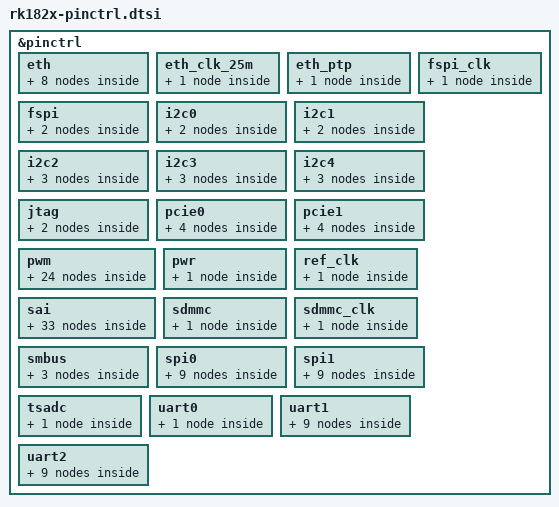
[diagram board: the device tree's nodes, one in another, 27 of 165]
// SPDX-License-Identifier: (GPL-2.0+ OR MIT)
/*
 * Copyright (c) 2026 Rockchip Electronics Co., Ltd.
 */

#include <dt-bindings/pinctrl/rockchip.h>
#include "rk182x-pinconf.dtsi"

/*
 * This file is auto generated by pin2dts tool, please keep these code
 * by adding changes at end of this file.
 */
&pinctrl {
	eth {
		/omit-if-no-ref/
		eth_miim_pins: eth-miim-pins {
			rockchip,pins =
				<1 RK_PC2 1 &pcfg_pull_none>,
				<1 RK_PC3 1 &pcfg_pull_none>;
		};

		/omit-if-no-ref/
		eth_mclk_pins: eth-mclk-pins {
			rockchip,pins =
				<1 RK_PC5 1 &pcfg_pull_none>;
		};

		/omit-if-no-ref/
		eth_rx_bus2_pins: eth-rx-bus2-pins {
			rockchip,pins =
				<1 RK_PC0 1 &pcfg_pull_none>,
				<1 RK_PB4 1 &pcfg_pull_none>,
				<1 RK_PB5 1 &pcfg_pull_none>;
		};

		/omit-if-no-ref/
		eth_tx_bus2_pins: eth-tx-bus2-pins {
			rockchip,pins =
				<1 RK_PB2 1 &pcfg_pull_none>,
				<1 RK_PA6 1 &pcfg_pull_none>,
				<1 RK_PA7 1 &pcfg_pull_none>;
		};

		/omit-if-no-ref/
		eth_rgmii_clk_pins: eth-rgmii-clk-pins {
			rockchip,pins =
				<1 RK_PC1 1 &pcfg_pull_none>,
				<1 RK_PB3 1 &pcfg_pull_none>;
		};

		/omit-if-no-ref/
		eth_rgmii_bus_pins: eth-rgmii-bus-pins {
			rockchip,pins =
				<1 RK_PB6 1 &pcfg_pull_none>,
				<1 RK_PB7 1 &pcfg_pull_none>,
				<1 RK_PB0 1 &pcfg_pull_none>,
				<1 RK_PB1 1 &pcfg_pull_none>;
		};

		/omit-if-no-ref/
		eth_ppsclk_pins: eth-ppsclk-pins {
			rockchip,pins =
				<1 RK_PC7 1 &pcfg_pull_none>;
		};

		/omit-if-no-ref/
		eth_ppstrig_pins: eth-ppstrig-pins {
			rockchip,pins =
				<1 RK_PD0 1 &pcfg_pull_none>;
		};
	};

	eth_clk_25m {
		/omit-if-no-ref/
		eth_clk_25m_out_pins: eth-clk-25m-out-pins {
			rockchip,pins =
				<1 RK_PC4 1 &pcfg_pull_none>;
		};
	};

	eth_ptp {
		/omit-if-no-ref/
		eth_ptp_refclk_pins: eth-ptp-refclk-pins {
			rockchip,pins =
				<1 RK_PC6 1 &pcfg_pull_none>;
		};
	};

	fspi {
		/omit-if-no-ref/
		fspi_bus4_pins: fspi-bus4-pins {
			rockchip,pins =
				<0 RK_PC4 1 &pcfg_pull_none>,
				<0 RK_PC5 1 &pcfg_pull_none>,
				<0 RK_PC6 1 &pcfg_pull_none>,
				<0 RK_PC7 1 &pcfg_pull_none>;
		};

		/omit-if-no-ref/
		fspi_csn_pins: fspi-csn-pins {
			rockchip,pins =
				<0 RK_PD0 1 &pcfg_pull_none>;
		};
	};

	fspi_clk {
		/omit-if-no-ref/
		fspi_clk_out_pins: fspi-clk-out-pins {
			rockchip,pins =
				<0 RK_PD1 1 &pcfg_pull_none>;
		};
	};

	i2c0 {
		/omit-if-no-ref/
		i2c0m0_pins: i2c0m0-pins {
			rockchip,pins =
				<0 RK_PA5 1 &pcfg_pull_none_smt>,
				<0 RK_PA6 1 &pcfg_pull_none_smt>;
		};

		/omit-if-no-ref/
		i2c0m1_pins: i2c0m1-pins {
			rockchip,pins =
				<1 RK_PB0 2 &pcfg_pull_none_smt>,
				<1 RK_PB1 2 &pcfg_pull_none_smt>;
		};
	};

	i2c1 {
		/omit-if-no-ref/
		i2c1m0_pins: i2c1m0-pins {
			rockchip,pins =
				<0 RK_PA7 1 &pcfg_pull_none_smt>,
				<0 RK_PB0 1 &pcfg_pull_none_smt>;
		};

		/omit-if-no-ref/
		i2c1m1_pins: i2c1m1-pins {
			rockchip,pins =
				<1 RK_PB3 2 &pcfg_pull_none_smt>,
				<1 RK_PB6 2 &pcfg_pull_none_smt>;
		};
	};

	i2c2 {
		/omit-if-no-ref/
		i2c2m0_pins: i2c2m0-pins {
			rockchip,pins =
				<0 RK_PB5 1 &pcfg_pull_none_smt>,
				<0 RK_PB6 1 &pcfg_pull_none_smt>;
		};

		/omit-if-no-ref/
		i2c2m1_pins: i2c2m1-pins {
			rockchip,pins =
				<1 RK_PC4 2 &pcfg_pull_none_smt>,
				<1 RK_PC5 2 &pcfg_pull_none_smt>;
		};

		/omit-if-no-ref/
		i2c2m2_pins: i2c2m2-pins {
			rockchip,pins =
				<1 RK_PA0 2 &pcfg_pull_none_smt>,
				<1 RK_PA1 2 &pcfg_pull_none_smt>;
		};
	};

	i2c3 {
		/omit-if-no-ref/
		i2c3m0_pins: i2c3m0-pins {
			rockchip,pins =
				<0 RK_PB3 1 &pcfg_pull_none_smt>,
				<0 RK_PB4 1 &pcfg_pull_none_smt>;
		};

		/omit-if-no-ref/
		i2c3m1_pins: i2c3m1-pins {
			rockchip,pins =
				<1 RK_PD2 2 &pcfg_pull_none_smt>,
				<1 RK_PD3 2 &pcfg_pull_none_smt>;
		};

		/omit-if-no-ref/
		i2c3m2_pins: i2c3m2-pins {
			rockchip,pins =
				<1 RK_PA4 2 &pcfg_pull_none_smt>,
				<1 RK_PA5 2 &pcfg_pull_none_smt>;
		};
	};

	i2c4 {
		/omit-if-no-ref/
		i2c4m0_pins: i2c4m0-pins {
			rockchip,pins =
				<1 RK_PD6 2 &pcfg_pull_none_smt>,
				<1 RK_PD7 2 &pcfg_pull_none_smt>;
		};

		/omit-if-no-ref/
		i2c4m1_pins: i2c4m1-pins {
			rockchip,pins =
				<1 RK_PB7 2 &pcfg_pull_none_smt>,
				<1 RK_PC1 2 &pcfg_pull_none_smt>;
		};

		/omit-if-no-ref/
		i2c4m2_pins: i2c4m2-pins {
			rockchip,pins =
				<0 RK_PD6 2 &pcfg_pull_none_smt>,
				<0 RK_PD7 2 &pcfg_pull_none_smt>;
		};
	};

	jtag {
		/omit-if-no-ref/
		jtagm0_pins: jtagm0-pins {
			rockchip,pins =
				<0 RK_PC0 1 &pcfg_pull_none>,
				<0 RK_PC1 1 &pcfg_pull_none>;
		};

		/omit-if-no-ref/
		jtagm1_pins: jtagm1-pins {
			rockchip,pins =
				<0 RK_PC2 1 &pcfg_pull_none>,
				<0 RK_PC3 1 &pcfg_pull_none>;
		};
	};

	pcie0 {
		/omit-if-no-ref/
		pcie0m0_pins: pcie0m0-pins {
			rockchip,pins =
				<0 RK_PB7 3 &pcfg_pull_none>;
		};

		/omit-if-no-ref/
		pcie0m1_pins: pcie0m1-pins {
			rockchip,pins =
				<1 RK_PD5 1 &pcfg_pull_none>;
		};

		/omit-if-no-ref/
		pcie0m2_pins: pcie0m2-pins {
			rockchip,pins =
				<1 RK_PC3 2 &pcfg_pull_none>;
		};

		/omit-if-no-ref/
		pcie0_buttonrstn_pins: pcie0-buttonrstn-pins {
			rockchip,pins =
				<0 RK_PA4 4 &pcfg_pull_none>;
		};
	};

	pcie1 {
		/omit-if-no-ref/
		pcie1m0_pins: pcie1m0-pins {
			rockchip,pins =
				<1 RK_PD1 2 &pcfg_pull_none>;
		};

		/omit-if-no-ref/
		pcie1m1_pins: pcie1m1-pins {
			rockchip,pins =
				<1 RK_PA5 5 &pcfg_pull_none>;
		};

		/omit-if-no-ref/
		pcie1m2_pins: pcie1m2-pins {
			rockchip,pins =
				<1 RK_PB2 2 &pcfg_pull_none>;
		};

		/omit-if-no-ref/
		pcie1_buttonrstn_pins: pcie1-buttonrstn-pins {
			rockchip,pins =
				<0 RK_PA3 4 &pcfg_pull_none>;
		};
	};

	pwm {
		/omit-if-no-ref/
		pwmm0_ch0_pins: pwmm0-ch0-pins {
			rockchip,pins =
				<0 RK_PA3 2 &pcfg_pull_none>;
		};
		/omit-if-no-ref/
		pwmm0_ch1_pins: pwmm0-ch1-pins {
			rockchip,pins =
				<0 RK_PA4 2 &pcfg_pull_none>;
		};
		/omit-if-no-ref/
		pwmm0_ch2_pins: pwmm0-ch2-pins {
			rockchip,pins =
				<0 RK_PA7 2 &pcfg_pull_none>;
		};
		/omit-if-no-ref/
		pwmm0_ch3_pins: pwmm0-ch3-pins {
			rockchip,pins =
				<0 RK_PB0 2 &pcfg_pull_none>;
		};
		/omit-if-no-ref/
		pwmm0_ch4_pins: pwmm0-ch4-pins {
			rockchip,pins =
				<0 RK_PB1 2 &pcfg_pull_none>;
		};
		/omit-if-no-ref/
		pwmm0_ch5_pins: pwmm0-ch5-pins {
			rockchip,pins =
				<0 RK_PB2 2 &pcfg_pull_none>;
		};
		/omit-if-no-ref/
		pwmm0_ch6_pins: pwmm0-ch6-pins {
			rockchip,pins =
				<0 RK_PB3 2 &pcfg_pull_none>;
		};
		/omit-if-no-ref/
		pwmm0_ch7_pins: pwmm0-ch7-pins {
			rockchip,pins =
				<0 RK_PB4 2 &pcfg_pull_none>;
		};

		/omit-if-no-ref/
		pwmm1_ch0_pins: pwmm1-ch0-pins {
			rockchip,pins =
				<1 RK_PA6 5 &pcfg_pull_none>;
		};
		/omit-if-no-ref/
		pwmm1_ch1_pins: pwmm1-ch1-pins {
			rockchip,pins =
				<1 RK_PA7 5 &pcfg_pull_none>;
		};
		/omit-if-no-ref/
		pwmm1_ch2_pins: pwmm1-ch2-pins {
			rockchip,pins =
				<1 RK_PB2 5 &pcfg_pull_none>;
		};
		/omit-if-no-ref/
		pwmm1_ch3_pins: pwmm1-ch3-pins {
			rockchip,pins =
				<1 RK_PB4 5 &pcfg_pull_none>;
		};
		/omit-if-no-ref/
		pwmm1_ch4_pins: pwmm1-ch4-pins {
			rockchip,pins =
				<1 RK_PB5 5 &pcfg_pull_none>;
		};
		/omit-if-no-ref/
		pwmm1_ch5_pins: pwmm1-ch5-pins {
			rockchip,pins =
				<1 RK_PC0 5 &pcfg_pull_none>;
		};
		/omit-if-no-ref/
		pwmm1_ch6_pins: pwmm1-ch6-pins {
			rockchip,pins =
				<1 RK_PD2 5 &pcfg_pull_none>;
		};
		/omit-if-no-ref/
		pwmm1_ch7_pins: pwmm1-ch7-pins {
			rockchip,pins =
				<1 RK_PD3 5 &pcfg_pull_none>;
		};

		/omit-if-no-ref/
		pwmm2_ch0_pins: pwmm2-ch0-pins {
			rockchip,pins =
				<1 RK_PC5 5 &pcfg_pull_none>;
		};
		/omit-if-no-ref/
		pwmm2_ch1_pins: pwmm2-ch1-pins {
			rockchip,pins =
				<1 RK_PC6 5 &pcfg_pull_none>;
		};
		/omit-if-no-ref/
		pwmm2_ch2_pins: pwmm2-ch2-pins {
			rockchip,pins =
				<1 RK_PC7 5 &pcfg_pull_none>;
		};
		/omit-if-no-ref/
		pwmm2_ch3_pins: pwmm2-ch3-pins {
			rockchip,pins =
				<1 RK_PD0 5 &pcfg_pull_none>;
		};
		/omit-if-no-ref/
		pwmm2_ch4_pins: pwmm2-ch4-pins {
			rockchip,pins =
				<1 RK_PD1 5 &pcfg_pull_none>;
		};
		/omit-if-no-ref/
		pwmm2_ch5_pins: pwmm2-ch5-pins {
			rockchip,pins =
				<1 RK_PD5 5 &pcfg_pull_none>;
		};
		/omit-if-no-ref/
		pwmm2_ch6_pins: pwmm2-ch6-pins {
			rockchip,pins =
				<1 RK_PD6 5 &pcfg_pull_none>;
		};
		/omit-if-no-ref/
		pwmm2_ch7_pins: pwmm2-ch7-pins {
			rockchip,pins =
				<1 RK_PD7 5 &pcfg_pull_none>;
		};
	};

	pwr {
		/omit-if-no-ref/
		pwr_pins: pwr-pins {
			rockchip,pins =
				<0 RK_PA2 1 &pcfg_pull_none>,
				<0 RK_PA3 1 &pcfg_pull_none>,
				<0 RK_PA4 1 &pcfg_pull_none>;
		};
	};

	ref_clk {
		/omit-if-no-ref/
		ref_clk_pins: ref-clk-pins {
			rockchip,pins =
				<0 RK_PA0 1 &pcfg_pull_none>;
		};
	};

	sai {
		/omit-if-no-ref/
		saim0_lrck_pins: saim0-lrck-pins {
			rockchip,pins =
				<0 RK_PB7 5 &pcfg_pull_none>;
		};

		/omit-if-no-ref/
		saim0_mclk_pins: saim0-mclk-pins {
			rockchip,pins =
				<0 RK_PC0 5 &pcfg_pull_none>;
		};

		/omit-if-no-ref/
		saim0_sclk_pins: saim0-sclk-pins {
			rockchip,pins =
				<0 RK_PB6 5 &pcfg_pull_none>;
		};

		/omit-if-no-ref/
		saim0_sdi0_pins: saim0-sdi0-pins {
			rockchip,pins =
				<0 RK_PB5 5 &pcfg_pull_none>;
		};

		/omit-if-no-ref/
		saim0_sdi1_pins: saim0-sdi1-pins {
			rockchip,pins =
				<0 RK_PB4 5 &pcfg_pull_none>;
		};

		/omit-if-no-ref/
		saim0_sdi2_pins: saim0-sdi2-pins {
			rockchip,pins =
				<0 RK_PB3 5 &pcfg_pull_none>;
		};

		/omit-if-no-ref/
		saim0_sdi3_pins: saim0-sdi3-pins {
			rockchip,pins =
				<0 RK_PC1 5 &pcfg_pull_none>;
		};

		/omit-if-no-ref/
		saim0_sdo0_pins: saim0-sdo0-pins {
			rockchip,pins =
				<0 RK_PC1 6 &pcfg_pull_none>;
		};

		/omit-if-no-ref/
		saim0_sdo1_pins: saim0-sdo1-pins {
			rockchip,pins =
				<0 RK_PB3 6 &pcfg_pull_none>;
		};

		/omit-if-no-ref/
		saim0_sdo2_pins: saim0-sdo2-pins {
			rockchip,pins =
				<0 RK_PB4 6 &pcfg_pull_none>;
		};

		/omit-if-no-ref/
		saim0_sdo3_pins: saim0-sdo3-pins {
			rockchip,pins =
				<0 RK_PB5 6 &pcfg_pull_none>;
		};

		/omit-if-no-ref/
		saim1_lrck_pins: saim1-lrck-pins {
			rockchip,pins =
				<0 RK_PD7 3 &pcfg_pull_none>;
		};

		/omit-if-no-ref/
		saim1_mclk_pins: saim1-mclk-pins {
			rockchip,pins =
				<1 RK_PA5 3 &pcfg_pull_none>;
		};

		/omit-if-no-ref/
		saim1_sclk_pins: saim1-sclk-pins {
			rockchip,pins =
				<0 RK_PD6 3 &pcfg_pull_none>;
		};

		/omit-if-no-ref/
		saim1_sdi0_pins: saim1-sdi0-pins {
			rockchip,pins =
				<1 RK_PA0 3 &pcfg_pull_none>;
		};

		/omit-if-no-ref/
		saim1_sdi1_pins: saim1-sdi1-pins {
			rockchip,pins =
				<1 RK_PA4 3 &pcfg_pull_none>;
		};

		/omit-if-no-ref/
		saim1_sdi2_pins: saim1-sdi2-pins {
			rockchip,pins =
				<0 RK_PD4 3 &pcfg_pull_none>;
		};

		/omit-if-no-ref/
		saim1_sdi3_pins: saim1-sdi3-pins {
			rockchip,pins =
				<0 RK_PD5 3 &pcfg_pull_none>;
		};

		/omit-if-no-ref/
		saim1_sdo0_pins: saim1-sdo0-pins {
			rockchip,pins =
				<1 RK_PA1 3 &pcfg_pull_none>;
		};

		/omit-if-no-ref/
		saim1_sdo1_pins: saim1-sdo1-pins {
			rockchip,pins =
				<1 RK_PA3 3 &pcfg_pull_none>;
		};

		/omit-if-no-ref/
		saim1_sdo2_pins: saim1-sdo2-pins {
			rockchip,pins =
				<0 RK_PD2 3 &pcfg_pull_none>;
		};

		/omit-if-no-ref/
		saim1_sdo3_pins: saim1-sdo3-pins {
			rockchip,pins =
				<0 RK_PD3 3 &pcfg_pull_none>;
		};

		/omit-if-no-ref/
		saim2_lrck_pins: saim2-lrck-pins {
			rockchip,pins =
				<1 RK_PD0 3 &pcfg_pull_none>;
		};

		/omit-if-no-ref/
		saim2_mclk_pins: saim2-mclk-pins {
			rockchip,pins =
				<1 RK_PC6 3 &pcfg_pull_none>;
		};

		/omit-if-no-ref/
		saim2_sclk_pins: saim2-sclk-pins {
			rockchip,pins =
				<1 RK_PC7 3 &pcfg_pull_none>;
		};

		/omit-if-no-ref/
		saim2_sdi0_pins: saim2-sdi0-pins {
			rockchip,pins =
				<1 RK_PD1 3 &pcfg_pull_none>;
		};

		/omit-if-no-ref/
		saim2_sdi1_pins: saim2-sdi1-pins {
			rockchip,pins =
				<1 RK_PD5 3 &pcfg_pull_none>;
		};

		/omit-if-no-ref/
		saim2_sdi2_pins: saim2-sdi2-pins {
			rockchip,pins =
				<1 RK_PD6 3 &pcfg_pull_none>;
		};

		/omit-if-no-ref/
		saim2_sdi3_pins: saim2-sdi3-pins {
			rockchip,pins =
				<1 RK_PD7 3 &pcfg_pull_none>;
		};

		/omit-if-no-ref/
		saim2_sdo0_pins: saim2-sdo0-pins {
			rockchip,pins =
				<1 RK_PD4 3 &pcfg_pull_none>;
		};

		/omit-if-no-ref/
		saim2_sdo1_pins: saim2-sdo1-pins {
			rockchip,pins =
				<1 RK_PC5 3 &pcfg_pull_none>;
		};

		/omit-if-no-ref/
		saim2_sdo2_pins: saim2-sdo2-pins {
			rockchip,pins =
				<1 RK_PC4 3 &pcfg_pull_none>;
		};

		/omit-if-no-ref/
		saim2_sdo3_pins: saim2-sdo3-pins {
			rockchip,pins =
				<1 RK_PD2 3 &pcfg_pull_none>;
		};
	};

	sdmmc {
		/omit-if-no-ref/
		sdmmc_pins: sdmmc-pins {
			rockchip,pins =
				<1 RK_PA2 1 &pcfg_pull_none>,
				<0 RK_PD2 1 &pcfg_pull_none>,
				<0 RK_PD3 1 &pcfg_pull_none>,
				<0 RK_PD4 1 &pcfg_pull_none>,
				<0 RK_PD5 1 &pcfg_pull_none>,
				<0 RK_PD6 1 &pcfg_pull_none>,
				<0 RK_PD7 1 &pcfg_pull_none>,
				<1 RK_PA0 1 &pcfg_pull_none>,
				<1 RK_PA1 1 &pcfg_pull_none>,
				<1 RK_PA5 1 &pcfg_pull_none>,
				<1 RK_PA4 1 &pcfg_pull_none>;
		};
	};

	sdmmc_clk {
		/omit-if-no-ref/
		sdmmc_clk_pins: sdmmc-clk-pins {
			rockchip,pins =
				<1 RK_PA3 1 &pcfg_pull_none>;
		};
	};

	smbus {
		/omit-if-no-ref/
		smbusm0_pins: smbusm0-pins {
			rockchip,pins =
				<0 RK_PB5 4 &pcfg_pull_none>,
				<0 RK_PB3 4 &pcfg_pull_none>,
				<0 RK_PB4 4 &pcfg_pull_none>;
		};

		/omit-if-no-ref/
		smbusm1_pins: smbusm1-pins {
			rockchip,pins =
				<1 RK_PD4 1 &pcfg_pull_none>,
				<1 RK_PD2 1 &pcfg_pull_none>,
				<1 RK_PD3 1 &pcfg_pull_none>;
		};

		/omit-if-no-ref/
		smbusm2_pins: smbusm2-pins {
			rockchip,pins =
				<1 RK_PA0 5 &pcfg_pull_none>,
				<0 RK_PD6 5 &pcfg_pull_none>,
				<0 RK_PD7 5 &pcfg_pull_none>;
		};
	};

	spi0 {
		/omit-if-no-ref/
		spi0m0_clk_pins: spi0m0-clk-pins {
			rockchip,pins =
				<0 RK_PA7 3 &pcfg_pull_none_drv_level_2_75>,
				<0 RK_PA6 3 &pcfg_pull_none_drv_level_2_75>,
				<0 RK_PB0 3 &pcfg_pull_none_drv_level_2_75>;
		};

		/omit-if-no-ref/
		spi0m0_cs0_pins: spi0m0-cs0-pins {
			rockchip,pins =
				<0 RK_PA5 3 &pcfg_pull_none_drv_level_2_75>;
		};

		/omit-if-no-ref/
		spi0m0_cs1_pins: spi0m0-cs1-pins {
			rockchip,pins =
				<0 RK_PA4 3 &pcfg_pull_none_drv_level_2_75>;
		};

		/omit-if-no-ref/
		spi0m1_clk_pins: spi0m1-clk-pins {
			rockchip,pins =
				<1 RK_PD1 6 &pcfg_pull_none_drv_level_2_75>,
				<1 RK_PD3 6 &pcfg_pull_none_drv_level_2_75>,
				<1 RK_PD2 6 &pcfg_pull_none_drv_level_2_75>;
		};

		/omit-if-no-ref/
		spi0m1_cs0_pins: spi0m1-cs0-pins {
			rockchip,pins =
				<1 RK_PD4 6 &pcfg_pull_none_drv_level_2_75>;
		};

		/omit-if-no-ref/
		spi0m1_cs1_pins: spi0m1-cs1-pins {
			rockchip,pins =
				<1 RK_PD5 6 &pcfg_pull_none_drv_level_2_75>;
		};

		/omit-if-no-ref/
		spi0m2_clk_pins: spi0m2-clk-pins {
			rockchip,pins =
				<1 RK_PB2 6 &pcfg_pull_none_drv_level_2_75>,
				<1 RK_PA7 6 &pcfg_pull_none_drv_level_2_75>,
				<1 RK_PA6 6 &pcfg_pull_none_drv_level_2_75>;
		};

		/omit-if-no-ref/
		spi0m2_cs0_pins: spi0m2-cs0-pins {
			rockchip,pins =
				<1 RK_PB4 6 &pcfg_pull_none_drv_level_2_75>;
		};

		/omit-if-no-ref/
		spi0m2_cs1_pins: spi0m2-cs1-pins {
			rockchip,pins =
				<1 RK_PB5 6 &pcfg_pull_none_drv_level_2_75>;
		};
	};

	spi1 {
		/omit-if-no-ref/
		spi1m0_clk_pins: spi1m0-clk-pins {
			rockchip,pins =
				<0 RK_PB3 3 &pcfg_pull_none_drv_level_2_75>,
				<0 RK_PB2 3 &pcfg_pull_none_drv_level_2_75>,
				<0 RK_PB4 3 &pcfg_pull_none_drv_level_2_75>;
		};

		/omit-if-no-ref/
		spi1m0_cs0_pins: spi1m0-cs0-pins {
			rockchip,pins =
				<0 RK_PB1 3 &pcfg_pull_none_drv_level_2_75>;
		};

		/omit-if-no-ref/
		spi1m0_cs1_pins: spi1m0-cs1-pins {
			rockchip,pins =
				<0 RK_PA3 3 &pcfg_pull_none_drv_level_2_75>;
		};

		/omit-if-no-ref/
		spi1m1_clk_pins: spi1m1-clk-pins {
			rockchip,pins =
				<1 RK_PD0 6 &pcfg_pull_none_drv_level_2_75>,
				<1 RK_PC6 6 &pcfg_pull_none_drv_level_2_75>,
				<1 RK_PC5 6 &pcfg_pull_none_drv_level_2_75>;
		};

		/omit-if-no-ref/
		spi1m1_cs0_pins: spi1m1-cs0-pins {
			rockchip,pins =
				<1 RK_PC7 6 &pcfg_pull_none_drv_level_2_75>;
		};

		/omit-if-no-ref/
		spi1m1_cs1_pins: spi1m1-cs1-pins {
			rockchip,pins =
				<1 RK_PC4 6 &pcfg_pull_none_drv_level_2_75>;
		};

		/omit-if-no-ref/
		spi1m2_clk_pins: spi1m2-clk-pins {
			rockchip,pins =
				<1 RK_PB3 6 &pcfg_pull_none_drv_level_2_75>,
				<1 RK_PB1 6 &pcfg_pull_none_drv_level_2_75>,
				<1 RK_PB0 6 &pcfg_pull_none_drv_level_2_75>;
		};

		/omit-if-no-ref/
		spi1m2_cs0_pins: spi1m2-cs0-pins {
			rockchip,pins =
				<1 RK_PB6 6 &pcfg_pull_none_drv_level_2_75>;
		};

		/omit-if-no-ref/
		spi1m2_cs1_pins: spi1m2-cs1-pins {
			rockchip,pins =
				<1 RK_PB7 6 &pcfg_pull_none_drv_level_2_75>;
		};
	};

	tsadc {
		/omit-if-no-ref/
		tsadc_pins: tsadc-pins {
			rockchip,pins =
				<0 RK_PA1 1 &pcfg_pull_none>;
		};
	};

	uart0 {
		/omit-if-no-ref/
		uart0_xfer_pins: uart0-xfer-pins {
			rockchip,pins =
				<0 RK_PC3 2 &pcfg_pull_up>,
				<0 RK_PC2 2 &pcfg_pull_up>;
		};
	};

	uart1 {
		/omit-if-no-ref/
		uart1m0_xfer_pins: uart1m0-xfer-pins {
			rockchip,pins =
				<0 RK_PC1 2 &pcfg_pull_up>,
				<0 RK_PC0 2 &pcfg_pull_up>;
		};

		/omit-if-no-ref/
		uart1m0_ctsn_pins: uart1m0-ctsn-pins {
			rockchip,pins =
				<0 RK_PB5 2 &pcfg_pull_none>;
		};
		/omit-if-no-ref/
		uart1m0_rtsn_pins: uart1m0-rtsn-pins {
			rockchip,pins =
				<0 RK_PB6 2 &pcfg_pull_none>;
		};

		/omit-if-no-ref/
		uart1m1_xfer_pins: uart1m1-xfer-pins {
			rockchip,pins =
				<1 RK_PD3 4 &pcfg_pull_up>,
				<1 RK_PD2 4 &pcfg_pull_up>;
		};

		/omit-if-no-ref/
		uart1m1_ctsn_pins: uart1m1-ctsn-pins {
			rockchip,pins =
				<1 RK_PD4 4 &pcfg_pull_none>;
		};
		/omit-if-no-ref/
		uart1m1_rtsn_pins: uart1m1-rtsn-pins {
			rockchip,pins =
				<1 RK_PD1 4 &pcfg_pull_none>;
		};

		/omit-if-no-ref/
		uart1m2_xfer_pins: uart1m2-xfer-pins {
			rockchip,pins =
				<0 RK_PD5 4 &pcfg_pull_up>,
				<0 RK_PD4 4 &pcfg_pull_up>;
		};

		/omit-if-no-ref/
		uart1m2_ctsn_pins: uart1m2-ctsn-pins {
			rockchip,pins =
				<0 RK_PD2 4 &pcfg_pull_none>;
		};
		/omit-if-no-ref/
		uart1m2_rtsn_pins: uart1m2-rtsn-pins {
			rockchip,pins =
				<0 RK_PD3 4 &pcfg_pull_none>;
		};
	};

	uart2 {
		/omit-if-no-ref/
		uart2m0_xfer_pins: uart2m0-xfer-pins {
			rockchip,pins =
				<1 RK_PD7 4 &pcfg_pull_up>,
				<1 RK_PD6 4 &pcfg_pull_up>;
		};

		/omit-if-no-ref/
		uart2m0_ctsn_pins: uart2m0-ctsn-pins {
			rockchip,pins =
				<1 RK_PC4 4 &pcfg_pull_none>;
		};
		/omit-if-no-ref/
		uart2m0_rtsn_pins: uart2m0-rtsn-pins {
			rockchip,pins =
				<1 RK_PC5 4 &pcfg_pull_none>;
		};

		/omit-if-no-ref/
		uart2m1_xfer_pins: uart2m1-xfer-pins {
			rockchip,pins =
				<0 RK_PC7 2 &pcfg_pull_up>,
				<0 RK_PC6 2 &pcfg_pull_up>;
		};

		/omit-if-no-ref/
		uart2m1_ctsn_pins: uart2m1-ctsn-pins {
			rockchip,pins =
				<0 RK_PC4 2 &pcfg_pull_none>;
		};
		/omit-if-no-ref/
		uart2m1_rtsn_pins: uart2m1-rtsn-pins {
			rockchip,pins =
				<0 RK_PC5 2 &pcfg_pull_none>;
		};

		/omit-if-no-ref/
		uart2m2_xfer_pins: uart2m2-xfer-pins {
			rockchip,pins =
				<0 RK_PD7 4 &pcfg_pull_up>,
				<0 RK_PD6 4 &pcfg_pull_up>;
		};

		/omit-if-no-ref/
		uart2m2_ctsn_pins: uart2m2-ctsn-pins {
			rockchip,pins =
				<1 RK_PA0 4 &pcfg_pull_none>;
		};
		/omit-if-no-ref/
		uart2m2_rtsn_pins: uart2m2-rtsn-pins {
			rockchip,pins =
				<1 RK_PA1 4 &pcfg_pull_none>;
		};
	};
};
